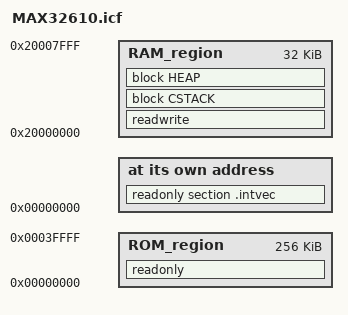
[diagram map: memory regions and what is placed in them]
/* [ROM] */
define symbol __intvec_start__        = 0x0;
define symbol __region_ROM_start__    = 0x0;
define symbol __region_ROM_end__      = 0x0003FFFF;

/* [RAM] Vector table dynamic copy: 79 vectors * 4 bytes = 316 bytes (0x13C) */
define symbol __NVIC_start__          = 0x00000000;
define symbol __NVIC_end__            = 0x00000140; /* to be aligned on 8 bytes */
define symbol __region_RAM_start__    = 0x20000000;
define symbol __region_RAM_end__      = 0x20007FFF;

/* Memory regions */
define memory mem with size = 4G;
define region ROM_region      = mem:[from __region_ROM_start__   to __region_ROM_end__];
define region RAM_region      = mem:[from __region_RAM_start__   to __region_RAM_end__];

/* Stack and Heap */
define symbol __size_cstack__ = 0x800;
define symbol __size_heap__   = 0x800;
define block CSTACK    with alignment = 8, size = __size_cstack__   { };
define block HEAP      with alignment = 8, size = __size_heap__     { };

initialize by copy { readwrite };
do not initialize  { section .noinit };

place at address mem:__intvec_start__ { readonly section .intvec };
place in ROM_region   { readonly };
place in RAM_region   { readwrite,
                        block CSTACK, block HEAP };
